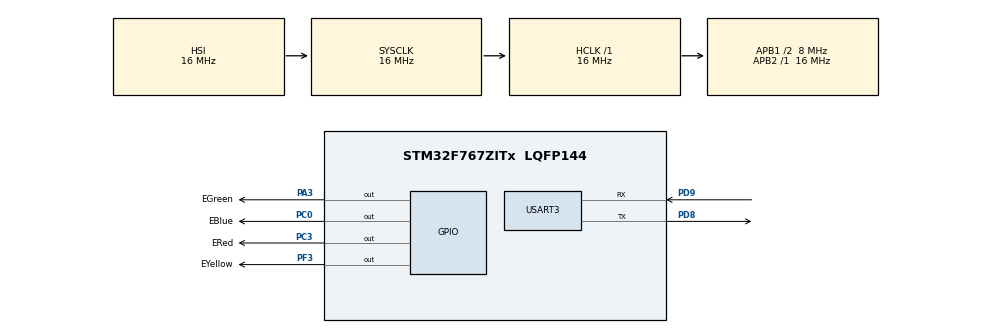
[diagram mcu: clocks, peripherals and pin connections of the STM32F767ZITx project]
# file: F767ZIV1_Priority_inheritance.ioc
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Mcu.Family=STM32F7
RCC.CortexFreq_Value=16000000
RCC.SYSCLKSourceVirtual=RCC_SYSCLKSOURCE_PLLCLK
PC0.GPIO_Label=EBlue
PD9.Mode=Asynchronous
ProjectManager.StackSize=0x400
USART3.VirtualMode-Asynchronous=VM_ASYNC
RCC.HCLKFreq_Value=16000000
RCC.APB2TimFreq_Value=16000000
PC3.Signal=GPIO_Output
PD8.Signal=USART3_TX
RCC.AHBFreq_Value=16000000
RCC.HSE_VALUE=16000000
RCC.PLLMUL=RCC_PLL_MUL9
PA14.Mode=Serial_Wire
VP_SYS_VS_tim1.Mode=TIM1
PF3.Signal=GPIO_Output
VP_FREERTOS_VS_CMSIS_V1.Mode=CMSIS_V1
Mcu.Package=LQFP144
NVIC.TimeBase=TIM1_UP_TIM10_IRQn
NVIC.TimeBaseIP=TIM1
RCC.APB1TimFreq_Value=16000000
PF3.GPIO_Label=EYellow
PA3.Signal=GPIO_Output
FREERTOS.Tasks01=toggleRed,2,128,toggleRedHook,Default,NULL,Dynamic,NULL,NULL;toggleGreen,0,128,toggleGreenHook,Default,NULL,Dynamic,NULL,NULL;toggleYellow,1,128,toggleYellowHook,Default,NULL,Dynamic,NULL,NULL
PD9.Signal=USART3_RX
PC0.Signal=GPIO_Output
RCC.APB1CLKDivider=RCC_HCLK_DIV2
PA13.Signal=SYS_JTMS-SWDIO
ProjectManager.TargetToolchain=STM32CubeIDE
RCC.USBFreq_Value=96000000
RCC.LSE_VALUE=32768
PD8.Mode=Asynchronous
board=NUCLEO-F767ZI
RCC.VCOOutputFreq_Value=192000000
RCC.APB2Freq_Value=16000000
RCC.PRESCALERUSB=RCC_USBCLKSOURCE_PLL_DIV1_5
PA13.Mode=Serial_Wire
Mcu.Name=STM32F767ZITx
RCC.48MHZClocksFreq_Value=24000000
RCC.SYSCLKFreq_VALUE=16000000
PA14.Signal=SYS_JTCK-SWCLK
ProjectManager.HeapSize=0x200
NVIC.TIM1_UP_TIM10_IRQn=true\:0\:0\:false\:false\:true\:false\:false\:true
RCC.HSI_VALUE=16000000
FREERTOS.Mutexes01=sharedFunctionMutex,Dynamic,NULL
NVIC.PriorityGroup=NVIC_PRIORITYGROUP_4
PC3.GPIO_Label=ERed
RCC.APB1Freq_Value=8000000
PA3.GPIO_Label=EGreen

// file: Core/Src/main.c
/* USER CODE BEGIN Header */
/**
  ******************************************************************************
  * @file           : main.c
  * @brief          : Main program body
  ******************************************************************************
  * @attention
  *
  * <h2><center>&copy; Copyright (c) 2021 STMicroelectronics.
  * All rights reserved.</center></h2>
  *
  * This software component is licensed by ST under Ultimate Liberty license
  * SLA0044, the "License"; You may not use this file except in compliance with
  * the License. You may obtain a copy of the License at:
  *                             www.st.com/SLA0044
  *
  ******************************************************************************
  */
/* USER CODE END Header */
#include "main.h"
#include "cmsis_os.h"

UART_HandleTypeDef huart3;

osThreadId toggleRedHandle;
osThreadId toggleGreenHandle;
osThreadId toggleYellowHandle;
osMutexId sharedFunctionMutexHandle;

void SystemClock_Config(void);
static void MX_GPIO_Init(void);
static void MX_USART3_UART_Init(void);
void toggleRedHook(void const * argument);
void toggleGreenHook(void const * argument);
void toggleYellowHook(void const * argument);

/* USER CODE BEGIN 0 */
void shared_function(uint8_t* msg, int n, GPIO_TypeDef* GPIOx, uint16_t GPIO_Pin);
/* USER CODE END 0 */

int main(void)
{

  /* MCU Configuration--------------------------------------------------------*/

  /* Reset of all peripherals, Initializes the Flash interface and the Systick. */
  HAL_Init();

  /* Configure the system clock */
  SystemClock_Config();

  /* Initialize all configured peripherals */
  MX_GPIO_Init();
  MX_USART3_UART_Init();

  /* Create the mutex(es) */
  /* definition and creation of sharedFunctionMutex */
  osMutexDef(sharedFunctionMutex);
  sharedFunctionMutexHandle = osMutexCreate(osMutex(sharedFunctionMutex));

  /* Create the thread(s) */
  /* definition and creation of toggleRed */
  osThreadDef(toggleRed, toggleRedHook, osPriorityHigh, 0, 128);
  toggleRedHandle = osThreadCreate(osThread(toggleRed), NULL);

  /* definition and creation of toggleGreen */
  osThreadDef(toggleGreen, toggleGreenHook, osPriorityNormal, 0, 128);
  toggleGreenHandle = osThreadCreate(osThread(toggleGreen), NULL);

  /* definition and creation of toggleYellow */
  osThreadDef(toggleYellow, toggleYellowHook, osPriorityAboveNormal, 0, 128);
  toggleYellowHandle = osThreadCreate(osThread(toggleYellow), NULL);

  /* Start scheduler */
  osKernelStart();

  /* We should never get here as control is now taken by the scheduler */
  /* Infinite loop */
  while (1)
  {

  }
}

void SystemClock_Config(void)
{
  RCC_OscInitTypeDef RCC_OscInitStruct = {0};
  RCC_ClkInitTypeDef RCC_ClkInitStruct = {0};
  RCC_PeriphCLKInitTypeDef PeriphClkInitStruct = {0};

  /** Configure the main internal regulator output voltage
  */
  __HAL_RCC_PWR_CLK_ENABLE();
  __HAL_PWR_VOLTAGESCALING_CONFIG(PWR_REGULATOR_VOLTAGE_SCALE3);
  /** Initializes the RCC Oscillators according to the specified parameters
  * in the RCC_OscInitTypeDef structure.
  */
  RCC_OscInitStruct.OscillatorType = RCC_OSCILLATORTYPE_HSI;
  RCC_OscInitStruct.HSIState = RCC_HSI_ON;
  RCC_OscInitStruct.HSICalibrationValue = RCC_HSICALIBRATION_DEFAULT;
  RCC_OscInitStruct.PLL.PLLState = RCC_PLL_NONE;
  if (HAL_RCC_OscConfig(&RCC_OscInitStruct) != HAL_OK)
  {
    Error_Handler();
  }
  /** Initializes the CPU, AHB and APB buses clocks
  */
  RCC_ClkInitStruct.ClockType = RCC_CLOCKTYPE_HCLK|RCC_CLOCKTYPE_SYSCLK
                              |RCC_CLOCKTYPE_PCLK1|RCC_CLOCKTYPE_PCLK2;
  RCC_ClkInitStruct.SYSCLKSource = RCC_SYSCLKSOURCE_HSI;
  RCC_ClkInitStruct.AHBCLKDivider = RCC_SYSCLK_DIV1;
  RCC_ClkInitStruct.APB1CLKDivider = RCC_HCLK_DIV2;
  RCC_ClkInitStruct.APB2CLKDivider = RCC_HCLK_DIV1;

  if (HAL_RCC_ClockConfig(&RCC_ClkInitStruct, FLASH_LATENCY_0) != HAL_OK)
  {
    Error_Handler();
  }
  PeriphClkInitStruct.PeriphClockSelection = RCC_PERIPHCLK_USART3;
  PeriphClkInitStruct.Usart3ClockSelection = RCC_USART3CLKSOURCE_PCLK1;
  if (HAL_RCCEx_PeriphCLKConfig(&PeriphClkInitStruct) != HAL_OK)
  {
    Error_Handler();
  }
}

static void MX_USART3_UART_Init(void)
{

  huart3.Instance = USART3;
  huart3.Init.BaudRate = 115200;
  huart3.Init.WordLength = UART_WORDLENGTH_8B;
  huart3.Init.StopBits = UART_STOPBITS_1;
  huart3.Init.Parity = UART_PARITY_NONE;
  huart3.Init.Mode = UART_MODE_TX_RX;
  huart3.Init.HwFlowCtl = UART_HWCONTROL_NONE;
  huart3.Init.OverSampling = UART_OVERSAMPLING_16;
  huart3.Init.OneBitSampling = UART_ONE_BIT_SAMPLE_DISABLE;
  huart3.AdvancedInit.AdvFeatureInit = UART_ADVFEATURE_NO_INIT;
  if (HAL_UART_Init(&huart3) != HAL_OK)
  {
    Error_Handler();
  }

}

static void MX_GPIO_Init(void)
{
  GPIO_InitTypeDef GPIO_InitStruct = {0};

  /* GPIO Ports Clock Enable */
  __HAL_RCC_GPIOF_CLK_ENABLE();
  __HAL_RCC_GPIOC_CLK_ENABLE();
  __HAL_RCC_GPIOA_CLK_ENABLE();
  __HAL_RCC_GPIOD_CLK_ENABLE();

  /*Configure GPIO pin Output Level */
  HAL_GPIO_WritePin(EYellow_GPIO_Port, EYellow_Pin, GPIO_PIN_RESET);

  /*Configure GPIO pin Output Level */
  HAL_GPIO_WritePin(GPIOC, EBlue_Pin|ERed_Pin, GPIO_PIN_RESET);

  /*Configure GPIO pin Output Level */
  HAL_GPIO_WritePin(EGreen_GPIO_Port, EGreen_Pin, GPIO_PIN_RESET);

  /*Configure GPIO pin : EYellow_Pin */
  GPIO_InitStruct.Pin = EYellow_Pin;
  GPIO_InitStruct.Mode = GPIO_MODE_OUTPUT_PP;
  GPIO_InitStruct.Pull = GPIO_NOPULL;
  GPIO_InitStruct.Speed = GPIO_SPEED_FREQ_LOW;
  HAL_GPIO_Init(EYellow_GPIO_Port, &GPIO_InitStruct);

  /*Configure GPIO pins : EBlue_Pin ERed_Pin */
  GPIO_InitStruct.Pin = EBlue_Pin|ERed_Pin;
  GPIO_InitStruct.Mode = GPIO_MODE_OUTPUT_PP;
  GPIO_InitStruct.Pull = GPIO_NOPULL;
  GPIO_InitStruct.Speed = GPIO_SPEED_FREQ_LOW;
  HAL_GPIO_Init(GPIOC, &GPIO_InitStruct);

  /*Configure GPIO pin : EGreen_Pin */
  GPIO_InitStruct.Pin = EGreen_Pin;
  GPIO_InitStruct.Mode = GPIO_MODE_OUTPUT_PP;
  GPIO_InitStruct.Pull = GPIO_NOPULL;
  GPIO_InitStruct.Speed = GPIO_SPEED_FREQ_LOW;
  HAL_GPIO_Init(EGreen_GPIO_Port, &GPIO_InitStruct);

}

void toggleRedHook(void const * argument)
{
	uint8_t tm1[50] = "RED: High: started and interrupted\n\r";
	uint8_t tm2[50] = "RED: High: competing for CS\n\r";
	uint8_t cm[50] =  "RED: High: acquired critical section\n\r";

	HAL_UART_Transmit(&huart3, tm1, sizeof(tm1), 100);
	/* Emulate task interruption */
	vTaskDelay(500);
	/* Resume execution and compete for the Critical Section (CS) */
	HAL_UART_Transmit(&huart3, tm2, sizeof(tm2), 100);
	shared_function(cm,sizeof(cm),ERed_GPIO_Port, ERed_Pin);

	/*A NULL handle will cause the calling task to be suspended */
	vTaskSuspend(NULL);
}

void toggleYellowHook(void const * argument)
{
	uint8_t tm1[50] = "YELLOW: AboveNormal: started and interrupted\n\r";
	uint8_t tm2[50] = "YELLOW: AboveNormal: competing for CS\n\r";
	uint8_t cm[50] =  "YELLOW: AboveNormal: acquired critical section\n\r";

	/* Task starts execution and is interrupted */
	HAL_UART_Transmit(&huart3, tm1, sizeof(tm1), 100);

	/* Emulate task interruption */
	vTaskDelay(700);

	HAL_UART_Transmit(&huart3, tm2, sizeof(tm2), 100);
	/* Compete for the CS */
	shared_function(cm, sizeof(cm), EYellow_GPIO_Port, EYellow_Pin);

	/*A NULL handle will cause the calling task to be suspended */
	vTaskSuspend(NULL);
}

void toggleGreenHook(void const * argument)
{
	uint8_t tm1[50] = "GREEN: Normal: started\n\r";
	uint8_t tm2[50] = "GREEN: Normal: competing for CS\n\r";
	uint8_t cm[50] =  "GREEN: Normal: acquired critical section\n\r";

	/* The task is not interrupted and immediately competes for the CS */
	HAL_UART_Transmit(&huart3, tm1, sizeof(tm1), 100);

	/* Competing for the Critical Section (CS) */
	HAL_UART_Transmit(&huart3, tm2, sizeof(tm2), 100);
	shared_function(cm,sizeof(cm),EGreen_GPIO_Port, EGreen_Pin);

	/*A NULL handle will cause the calling task to be suspended */
	vTaskSuspend(NULL);
}

void shared_function(uint8_t* msg, int n, GPIO_TypeDef* GPIOx, uint16_t GPIO_Pin) {
	osMutexWait(sharedFunctionMutexHandle, osWaitForever);

	TickType_t start = xTaskGetTickCount();  // 4s delay

	do {
			HAL_GPIO_TogglePin(EBlue_GPIO_Port, EBlue_Pin);
			HAL_GPIO_TogglePin(GPIOx, GPIO_Pin);
			for(int i=0; i<=630000; i++);   // Approximate delay of 10 Hz
			HAL_UART_Transmit(&huart3, msg, n, 100);
	} while((xTaskGetTickCount() - start) <= 4000);

	HAL_GPIO_WritePin(GPIOx, GPIO_Pin, GPIO_PIN_RESET);

	osMutexRelease(sharedFunctionMutexHandle);
}

 /**
  * @brief  Period elapsed callback in non blocking mode
  * @note   This function is called  when TIM1 interrupt took place, inside
  * HAL_TIM_IRQHandler(). It makes a direct call to HAL_IncTick() to increment
  * a global variable "uwTick" used as application time base.
  * @param  htim : TIM handle
  * @retval None
  */
void HAL_TIM_PeriodElapsedCallback(TIM_HandleTypeDef *htim)
{
  if (htim->Instance == TIM1) {
    HAL_IncTick();
  }
}

void Error_Handler(void)
{
  __disable_irq();
  while (1)
  {
  }
}

/************************ (C) COPYRIGHT STMicroelectronics *****END OF FILE****/
